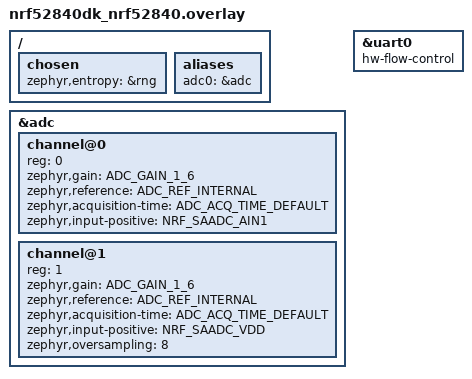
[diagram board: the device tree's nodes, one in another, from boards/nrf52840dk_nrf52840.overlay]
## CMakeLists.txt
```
#
# Copyright (c) 2020 Nordic Semiconductor ASA
#
# SPDX-License-Identifier: LicenseRef-Nordic-5-Clause
#
cmake_minimum_required(VERSION 3.20.0)

find_package(Zephyr REQUIRED HINTS $ENV{ZEPHYR_BASE})

project(audio-offload)

# NORDIC SDK APP START
target_sources(app PRIVATE src/main.c src/audio.c src/util.c)
# NORDIC SDK APP END

target_sources_ifdef(CONFIG_CLI_SAMPLE_MULTIPROTOCOL app PRIVATE src/ble.c)
target_sources_ifdef(CONFIG_CLI_SAMPLE_LOW_POWER app PRIVATE src/low_power.c)


if (CONFIG_CLI_SAMPLE_MULTIPROTOCOL AND CONFIG_OPENTHREAD_BLE_TCAT)
        message( FATAL_ERROR "Multiprotocol support and TCAT functionality are not compatible." )
endif()
```

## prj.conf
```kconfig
#
# Copyright (c) 2020 Nordic Semiconductor
#
# SPDX-License-Identifier: LicenseRef-Nordic-5-Clause
#

# Network shell
CONFIG_SHELL=y
CONFIG_OPENTHREAD_SHELL=y
CONFIG_SHELL_ARGC_MAX=26
CONFIG_SHELL_CMD_BUFF_SIZE=416

# Increase Settings storage size
CONFIG_PM_PARTITION_SIZE_SETTINGS_STORAGE=0x8000

# Enable OpenThread features set
CONFIG_OPENTHREAD_NORDIC_LIBRARY_MASTER=y

CONFIG_NET_L2_OPENTHREAD=y

# Generic networking options
CONFIG_NETWORKING=y

CONFIG_GPIO_SHELL=y

CONFIG_ADC=y

CONFIG_OPENTHREAD_JOINER=y
#CONFIG_OPENTHREAD_JOINER_AUTOSTART=y
CONFIG_OPENTHREAD_JOINER_PSKD="UVANET"
CONFIG_OPENTHREAD_MANUAL_START=n
# CONFIG_OPENTHREAD_SETTINGS_RAM=y

# CONFIG_OPENTHREAD_MTD=y
# CONFIG_OPENTHREAD_MTD_SED=y
# CONFIG_OPENTHREAD_POLL_PERIOD=2000

CONFIG_NET_SOCKETS=y
CONFIG_NET_SOCKETS_POSIX_NAMES=y
CONFIG_NET_SOCKETS_POLL_MAX=4
```

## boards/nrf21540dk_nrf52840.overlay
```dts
/* Copyright (c) 2020 Nordic Semiconductor ASA
 *
 * SPDX-License-Identifier: LicenseRef-Nordic-5-Clause
 */

/* Default Zephyr configuration already provides GPIO support for FEM. */

&uart0 {
	status = "okay";
	hw-flow-control;
};

&adc {
 status = "okay";
 #address-cells = <1>;
 #size-cells = <0>;

 channel@0 {
  reg = <0>;
  zephyr,gain = "ADC_GAIN_1_6";
  zephyr,reference = "ADC_REF_INTERNAL";
  zephyr,acquisition-time = <0>;
  zephyr,input-positive = <2>;
 };

 channel@1 {
  reg = <1>;
  zephyr,gain = "ADC_GAIN_1_6";
  zephyr,reference = "ADC_REF_INTERNAL";
  zephyr,acquisition-time = <0>;
  zephyr,input-positive = <9>;
  zephyr,oversampling = <8>;
 };
};

/ {
	/*
	* In some default configurations within the nRF Connect SDK,
	* e.g. on nRF52840, the chosen zephyr,entropy node is &cryptocell.
	* This devicetree overlay ensures that default is overridden wherever it
	* is set, as this application uses the RNG node for entropy exclusively.
	*/
	chosen {
		zephyr,entropy = &rng;
	};
};
```

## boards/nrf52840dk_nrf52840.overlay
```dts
/* Copyright (c) 2020 Nordic Semiconductor ASA
 *
 * SPDX-License-Identifier: LicenseRef-Nordic-5-Clause
 */

&adc {
	status = "okay";
	#address-cells = <1>;
	#size-cells = <0>;

	channel@0 {
		reg = <0>;
		zephyr,gain = "ADC_GAIN_1_6";
		zephyr,reference = "ADC_REF_INTERNAL";
		zephyr,acquisition-time = <ADC_ACQ_TIME_DEFAULT>;
		zephyr,input-positive = <NRF_SAADC_AIN1>; /* P0.03 */
	};

	channel@1 {
		reg = <1>;
		zephyr,gain = "ADC_GAIN_1_6";
		zephyr,reference = "ADC_REF_INTERNAL";
		zephyr,acquisition-time = <ADC_ACQ_TIME_DEFAULT>;
		zephyr,input-positive = <NRF_SAADC_VDD>;
		zephyr,oversampling = <8>;
	};
};

&uart0 {
	status = "okay";
	hw-flow-control;
};

/ {
	/*
	* In some default configurations within the nRF Connect SDK,
	* e.g. on nRF52840, the chosen zephyr,entropy node is &cryptocell.
	* This devicetree overlay ensures that default is overridden wherever it
	* is set, as this application uses the RNG node for entropy exclusively.
	*/
	chosen {
		zephyr,entropy = &rng;
	};

	aliases {
		adc0 = &adc;
	};
};
```

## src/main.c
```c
/*
 * Copyright (c) 2020 Nordic Semiconductor ASA
 *
 * SPDX-License-Identifier: LicenseRef-Nordic-5-Clause
 */

#include <stdio.h>

#include <zephyr/drivers/adc.h>
#include <zephyr/drivers/uart.h>
#include <zephyr/kernel.h>
#include <zephyr/logging/log.h>
#include <zephyr/net/net_ip.h>
#include <zephyr/net/openthread.h>
#include <zephyr/net/socket.h>
#include <zephyr/usb/usb_device.h>

#include <openthread/ip6.h>
#include <openthread/thread.h>

#include "audio.h"
#include "util.h"

LOG_MODULE_REGISTER(cli_sample, CONFIG_OT_COMMAND_LINE_INTERFACE_LOG_LEVEL);

#define WELLCOME_TEXT \
	"\n\r"\
	"\n\r"\
	"OpenThread Command Line Interface is now running.\n\r"

#define DEST_IP "fde3:8f5e:f206:2::c0a8:023d"
#define DEST_PORT 25560
#define PAYLOAD_LEN_MAX 768

int main(void)
{
	LOG_INF(WELLCOME_TEXT);

	struct openthread_context* const ot_context = openthread_get_default_context();
	otInstance* const ot_instance = ot_context->instance;

	printf("Started.\n");

	bool thread_ready = false;
	printk("Awaiting Thread readiness.");
	while (!thread_ready)
	{
		openthread_api_mutex_lock(ot_context);
		const otNetifAddress* const ip6_addrs = otIp6GetUnicastAddresses(ot_instance);
		openthread_api_mutex_unlock(ot_context);

		uint8_t addr_count = 0;
		for (const otNetifAddress* if_addr = ip6_addrs;
				if_addr;
				if_addr = if_addr->mNext)
		{
			addr_count++;
		}

		// An uncertain check to see if Thread is ready.
		// printf("IP6 addr count: %d\n", addr_count);
		thread_ready = addr_count >= 4;

		k_msleep(1000);
	}

	printk(" Thread appears ready.\n");

	while (true)
	{
		k_msleep(3000);

		// Get audio.
		const uint16_t* const audio_samples = audio_record_audio();

		// Offload to controller for processing.
		int sock, err;
		struct sockaddr_in6 dest_addr;

		sock = socket(AF_INET6, SOCK_DGRAM, IPPROTO_UDP);
		if (sock < 0)
		{
				printf("Failed to create socket: %d\n", errno);
				failspin();
		}

		dest_addr.sin6_family = AF_INET6;
		dest_addr.sin6_port = htons(DEST_PORT);
		err = inet_pton(AF_INET6, DEST_IP, &dest_addr.sin6_addr);
		if (err <= 0)
		{
			printf("Invalid address: %d\n", err);
			failspin();
		}

		// printf("Sending audio data.\n");
		const uint32_t buffer_byte_len = ((uint32_t) (audio_samples + SAMPLE_BUFFER_LEN))
			- ((uint32_t) audio_samples);
		uint32_t bytes_sent = 0;
		while (bytes_sent < buffer_byte_len)
		{
			const uint32_t bytes_remaining = buffer_byte_len - bytes_sent;
			uint32_t payload_len = bytes_remaining < PAYLOAD_LEN_MAX ? bytes_remaining : PAYLOAD_LEN_MAX;
			// printf("remaining: %d, payload len: %d\n", bytes_remaining, payload_len);
			err = sendto(
				sock,
				(const void*) (((uint8_t* const) audio_samples) + bytes_sent),
				payload_len,
				0,
				(struct sockaddr*) &dest_addr,
				sizeof(dest_addr));
			if (err < 0)
			{
				printf("sendto failed: %d\n", errno);
				break;
			}

			bytes_sent += payload_len;
			// printf("Sent %d B of %d B of audio data.\n", bytes_sent, buffer_byte_len);
		}
		close(sock);
		// printf("Sent %d bytes of audio data.\n", bytes_sent);
	}

	return 0;
}
```

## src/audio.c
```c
#include <stdint.h>
#include <stdio.h>

#include <zephyr/drivers/adc.h>

#include "audio.h"
#include "util.h"

#define ADC_NODE DT_ALIAS(adc0)
static const struct device* adc = DEVICE_DT_GET(ADC_NODE);
static const struct adc_channel_cfg channel_cfgs[] = {
    DT_FOREACH_CHILD_SEP(ADC_NODE, ADC_CHANNEL_CFG_DT, (,))
};

#define CHANNEL_COUNT ARRAY_SIZE(channel_cfgs)

uint16_t SAMPLE_BUFFER[SAMPLE_BUFFER_LEN];

const uint16_t* audio_record_audio(void)
{
    int err;

    return SAMPLE_BUFFER;

	// Set up ADC.
	const struct adc_sequence_options sequence_options = {
		.interval_us = 1000000 / SAMPLE_FREQ,
		.extra_samplings = SAMPLE_BUFFER_LEN - 1,
	};

	struct adc_sequence sampling_sequence = {
		.options = &sequence_options,
		.buffer = SAMPLE_BUFFER,
		.buffer_size = sizeof(SAMPLE_BUFFER),
		.resolution = 12,
	};

	while (!device_is_ready(adc))
	{
		k_msleep(1000);
	}

	sampling_sequence.channels = 1;
	err = adc_channel_setup(adc, &channel_cfgs[0]);
	if (err < 0)
	{
		printf("could not set up channel\n");
		failspin();
	}

    err = adc_read(adc, &sampling_sequence);
    if (err < 0)
    {
        printf("failed to sample audio");
        failspin();
    }

    return SAMPLE_BUFFER;
}

const uint16_t* audio_record_audio_raw(void)
{

    // Configure the ADC for 12-bit resolution
    NRF_SAADC->RESOLUTION = SAADC_RESOLUTION_VAL_12bit;

    // Configure channel 0 for single-ended input from AIN0
    NRF_SAADC->CH[0].PSELP = SAADC_CH_PSELP_PSELP_AnalogInput0;
    NRF_SAADC->CH[0].PSELN = SAADC_CH_PSELN_PSELN_NC;

    // Configure channel 0 with gain of 1/4, VDD/4 reference, and 10us acquisition time
    NRF_SAADC->CH[0].CONFIG = (SAADC_CH_CONFIG_RESP_Bypass << SAADC_CH_CONFIG_RESP_Pos) |
                              (SAADC_CH_CONFIG_RESN_Bypass << SAADC_CH_CONFIG_RESN_Pos) |
                              (SAADC_CH_CONFIG_GAIN_Gain1_4 << SAADC_CH_CONFIG_GAIN_Pos) |
                              (SAADC_CH_CONFIG_REFSEL_VDD1_4 << SAADC_CH_CONFIG_REFSEL_Pos) |
                              (SAADC_CH_CONFIG_TACQ_10us << SAADC_CH_CONFIG_TACQ_Pos) |
                              (SAADC_CH_CONFIG_MODE_SE << SAADC_CH_CONFIG_MODE_Pos);


    // Configure the sample rate
    // For 22050 Hz, CC = 16 MHz / 22050 Hz = 725.62
    // Round up to 726
    NRF_SAADC->SAMPLERATE = (726 << SAADC_SAMPLERATE_CC_Pos) |
                            (SAADC_SAMPLERATE_MODE_Timers << SAADC_SAMPLERATE_MODE_Pos);

    // Configure EasyDMA
    // NRF_SAADC->RESULT.PTR = (uint32_t) SAMPLE_BUFFER;
    uint32_t* const saadc_result_ptr = (uint32_t*) (0x40007000 + 0x62C);
    *saadc_result_ptr = (uint32_t) SAMPLE_BUFFER;
    // NRF_SAADC->RESULT.MAXCNT = SAMPLE_BUFFER_LEN;
    uint32_t* const saadc_result_maxcnt = (uint32_t*) (0x40007000 + 0x630);
    *saadc_result_maxcnt = SAMPLE_BUFFER_LEN;

    // uint32_t* const rtc_intenset = (uint32_t*) (0x40008000 + 0x304);
    // uint32_t* const rtc_intenclr = (uint32_t*) (0x40008000 + 0x308);
    // *rtc_intenclr = (1 << 19) | (1 << 18) | (1 << 17) | (1 << 16) | (1 << 1) | (1 << 0);

    // Enable the ADC
    NRF_SAADC->ENABLE = SAADC_ENABLE_ENABLE_Enabled;

    // Start the ADC
    NRF_SAADC->TASKS_START = 1;

    while(true);
    while ((NRF_SAADC->EVENTS_END & 1) == 0) {  }

    return SAMPLE_BUFFER;
}
```

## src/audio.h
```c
#include <stdint.h>

#define SAMPLE_TIME_SECS 1
#define SAMPLE_FREQ 22050
#define SAMPLE_BUFFER_LEN (SAMPLE_FREQ * SAMPLE_TIME_SECS)

const uint16_t* audio_record_audio(void);
const uint16_t* audio_record_audio_raw(void);
```

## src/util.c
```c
#include <zephyr/kernel.h>

void failspin(void)
{
	while (true) { k_msleep(1000); }
}
```

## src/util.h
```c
void failspin(void);
```
